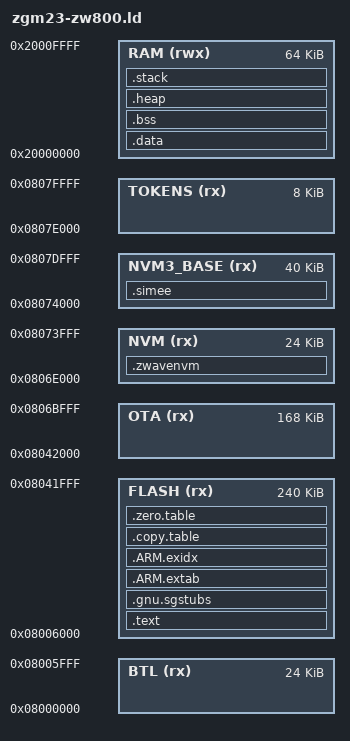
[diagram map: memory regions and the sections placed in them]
/***************************************************************************//**
 * @file     gcc_ZGM23.ld
 * @brief    GNU Linker Script for Cortex-M based device
 * @version  V2.2.0
 * @date     16. December 2020
 * Linker script for Silicon Labs ZGM23 devices
 *******************************************************************************
 * # License
 * <b>Copyright 2022 Silicon Laboratories, Inc. www.silabs.com </b>
 *******************************************************************************
 *
 * SPDX-License-Identifier: Zlib
 * 
 * The licensor of this software is Silicon Laboratories Inc.
 * 
 * This software is provided 'as-is', without any express or implied
 * warranty. In no event will the authors be held liable for any damages
 * arising from the use of this software.
 * 
 * Permission is granted to anyone to use this software for any purpose,
 * including commercial applications, and to alter it and redistribute it
 * freely, subject to the following restrictions:
 * 
 * 1. The origin of this software must not be misrepresented; you must not
 *    claim that you wrote the original software. If you use this software
 *    in a product, an acknowledgment in the product documentation would be
 *    appreciated but is not required.
 * 2. Altered source versions must be plainly marked as such, and must not be
 *    misrepresented as being the original software.
 * 3. This notice may not be removed or altered from any source distribution.
 *
 ******************************************************************************/

/*
 *-------- <<< Use Configuration Wizard in Context Menu >>> -------------------
 */
/*--------------------- Stack / Heap Configuration ----------------------------
  <h> Stack / Heap Configuration
    <o0> Stack Size (in Bytes) <0x0-0xFFFFFFFF:8>
    <o1> Heap Size (in Bytes) <0x0-0xFFFFFFFF:8>
  </h>
  -----------------------------------------------------------------------------*/
__STACK_SIZE = 0x00000280;
__HEAP_SIZE  = 0x00000180;

/*
 *-------------------- <<< end of configuration section >>> -------------------
 */

/*
*FLASH layout
* -------- 0x08000000 BOOTLOADER           size = 24K  ------
* -------- 0x08006000 Z-Wave image         size = 240K ------
* -------  0x08042000 OTA image            size = 168K ------
* -------  0x0806C000 GAP                  size = 8K   ------ 
* -------  0x0806E000 FS (NVM + NVM3_BASE) size = 64K  ------
* -------  0x0807E000 TOKENS               size = 8K   ------
*/

MEMORY
{
  BTL   (rx) : ORIGIN = 0x08000000, LENGTH = 24K
  FLASH (rx) : ORIGIN = 0x08006000, LENGTH = 240K
  OTA   (rx) : ORIGIN = 0x08042000, LENGTH = 168K
  NVM   (rx) : ORIGIN = 0x0806E000, LENGTH = 24K
  NVM3_BASE (rx) : ORIGIN = 0x08074000, LENGTH = 40K
  TOKENS    (rx) : ORIGIN = 0x0807E000, LENGTH = 8K
  RAM (rwx)  : ORIGIN = 0x20000000, LENGTH = 64K
}

/* Linker script to place sections and symbol values. Should be used together
 * with other linker script that defines memory regions FLASH and RAM.
 * It references following symbols, which must be defined in code:
 *   Reset_Handler : Entry of reset handler
 *
 * It defines following symbols, which code can use without definition:
 *   __exidx_start
 *   __exidx_end
 *   __copy_table_start__
 *   __copy_table_end__
 *   __zero_table_start__
 *   __zero_table_end__
 *   __etext
 *   __data_start__
 *   __preinit_array_start
 *   __preinit_array_end
 *   __init_array_start
 *   __init_array_end
 *   __fini_array_start
 *   __fini_array_end
 *   __data_end__
 *   __bss_start__
 *   __bss_end__
 *   __end__
 *   end
 *   __HeapBase
 *   __HeapLimit
 *   __StackLimit
 *   __StackTop
 *   __stack
 *   __StackSeal      (only if ARMv8-M stack sealing is used)
 */

ENTRY(Reset_Handler)

SECTIONS
{

  .zwavenvm (NOLOAD):
  {
    . = ALIGN(2048);
    _zwavenvm = . ;
    KEEP(*(.zwavenvm))
    _ezwavenvm = . ;
  } >NVM

  .simee (NOLOAD):
  {
    . = ALIGN(2048);
    _simee = . ;
    KEEP(*(.simee))
    _esimee = . ;
  } >NVM3_BASE



  .text :
  {
    KEEP(*(.vectors))
    *(.text*)

    KEEP(*(.init))
    KEEP(*(.fini))

    /* .ctors */
    *crtbegin.o(.ctors)
    *crtbegin?.o(.ctors)
    *(EXCLUDE_FILE(*crtend?.o *crtend.o) .ctors)
    *(SORT(.ctors.*))
    *(.ctors)

    /* .dtors */
    *crtbegin.o(.dtors)
    *crtbegin?.o(.dtors)
    *(EXCLUDE_FILE(*crtend?.o *crtend.o) .dtors)
    *(SORT(.dtors.*))
    *(.dtors)

    *(.rodata*)

    KEEP(*(.eh_frame*))

    /*We need to calculate the size of the cc_handlers to calculate the total FLASH space used*/
    /*This is useful to make an assert if the total FLASH space used is bigger than the FLASH max size*/
    __start__cc_handlers_v3 = .;
    KEEP(*(_cc_handlers_v3*))
    __stop__cc_handlers_v3 = .;
  } > FLASH

  /*
   * SG veneers:
   * All SG veneers are placed in the special output section .gnu.sgstubs. Its start address
   * must be set, either with the command line option ‘--section-start’ or in a linker script,
   * to indicate where to place these veneers in memory.
   */

  .gnu.sgstubs : ALIGN(32)
  {
    . = ALIGN(32);
    linker_sg_begin = .;
    KEEP(*(.gnu.sgstubs*))
    . = ALIGN(32);
  } > FLASH
  linker_sg_end = linker_sg_begin + SIZEOF(.gnu.sgstubs);

  .ARM.extab :
  {
    *(.ARM.extab* .gnu.linkonce.armextab.*)
  } > FLASH

  __exidx_start = .;
  .ARM.exidx :
  {
    *(.ARM.exidx* .gnu.linkonce.armexidx.*)
  } > FLASH
  __exidx_end = .;

  .copy.table :
  {
    . = ALIGN(4);
    __copy_table_start__ = .;

    LONG (__etext)
    LONG (__data_start__)
    LONG ((__data_end__ - __data_start__) / 4)

    /* Add each additional data section here */
/*
    LONG (__etext2)
    LONG (__data2_start__)
    LONG ((__data2_end__ - __data2_start__) / 4)
*/
    __copy_table_end__ = .;
  } > FLASH

  .zero.table :
  {
    . = ALIGN(4);
    __zero_table_start__ = .;
    /* Add each additional bss section here */
/*
    LONG (__bss2_start__)
    LONG ((__bss2_end__ - __bss2_start__) / 4)
*/
    __zero_table_end__ = .;
    __etext = ALIGN(4);
  } > FLASH


  .data : AT (__etext)
  {
    __data_start__ = .;
    *(vtable)
    *(.data*)
    . = ALIGN (4);
    PROVIDE (__ram_func_section_start = .);
    *(.ram)
    PROVIDE (__ram_func_section_end = .);

    . = ALIGN(4);
    /* preinit data */
    PROVIDE_HIDDEN (__preinit_array_start = .);
    KEEP(*(.preinit_array))
    PROVIDE_HIDDEN (__preinit_array_end = .);

    . = ALIGN(4);
    /* init data */
    PROVIDE_HIDDEN (__init_array_start = .);
    KEEP(*(SORT(.init_array.*)))
    KEEP(*(.init_array))
    PROVIDE_HIDDEN (__init_array_end = .);

    . = ALIGN(4);
    /* finit data */
    PROVIDE_HIDDEN (__fini_array_start = .);
    KEEP(*(SORT(.fini_array.*)))
    KEEP(*(.fini_array))
    PROVIDE_HIDDEN (__fini_array_end = .);

    KEEP(*(.jcr*))
    . = ALIGN(4);
    /* All data end */
    __data_end__ = .;

  } > RAM

  /*
   * Secondary data section, optional
   *
   * Remember to add each additional data section
   * to the .copy.table above to asure proper
   * initialization during startup.
   */
/*
  __etext2 = ALIGN (4);

  .data2 : AT (__etext2)
  {
    . = ALIGN(4);
    __data2_start__ = .;
    *(.data2)
    *(.data2.*)
    . = ALIGN(4);
    __data2_end__ = .;

  } > RAM2
*/
  .bss :
  {
    . = ALIGN(4);
    __bss_start__ = .;
    *(.bss)
    *(.bss.*)
    *(COMMON)
    . = ALIGN(4);
    __bss_end__ = .;
  } > RAM AT > RAM

  /*
   * Secondary bss section, optional
   *
   * Remember to add each additional bss section
   * to the .zero.table above to asure proper
   * initialization during startup.
   */
/*
  .bss2 :
  {
    . = ALIGN(4);
    __bss2_start__ = .;
    *(.bss2)
    *(.bss2.*)
    . = ALIGN(4);
    __bss2_end__ = .;
  } > RAM2 AT > RAM2
*/

  .heap (COPY) :
  {
    . = ALIGN(8);
    __HeapBase = .;
    __end__ = .;
    PROVIDE(end = .);
    . = . + __HEAP_SIZE;
    . = ALIGN(8);
    __HeapLimit = .;
  } > RAM

  .stack (ORIGIN(RAM) + LENGTH(RAM) - __STACK_SIZE) (COPY) :
  {
    . = ALIGN(8);
    __StackLimit = .;
    . = . + __STACK_SIZE;
    . = ALIGN(8);
    __StackTop = .;
  } > RAM
  PROVIDE(__stack = __StackTop);

  /* Check if data + heap + stack exceeds RAM limit */
  ASSERT(__StackLimit >= __HeapLimit, "region RAM overflowed with stack")

  /* Check if FLASH usage exceeds FLASH size */
  ASSERT( LENGTH(FLASH) >= ((__etext - ORIGIN(FLASH) ) + SIZEOF(.data)), "FLASH memory overflowed !")
}
